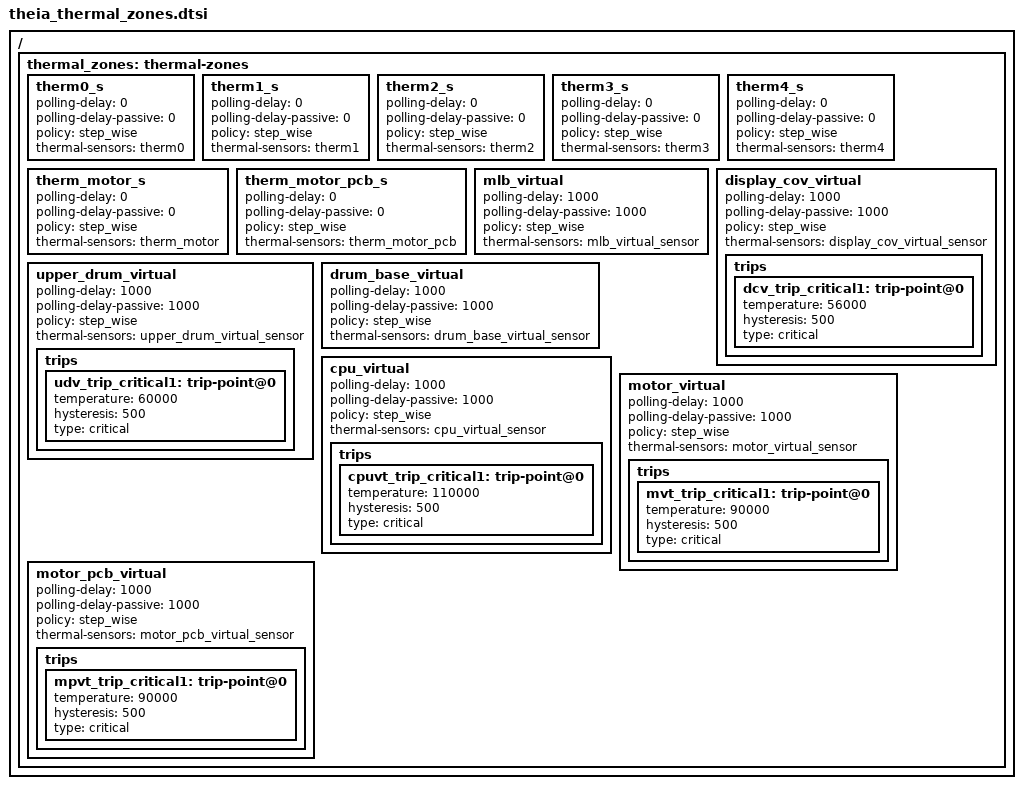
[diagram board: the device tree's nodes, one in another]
/*
 * arch/arm64/boot/dts/mediatek/theia_thermal_zones.dtsi
 *
 * Copyright (C) 2020 Amazon, Inc. All rights reserved.
 *
 * This program is free software; you can redistribute it and/or modify
 * it under the terms of the GNU General Public License as published by
 * the Free Software Foundation; either version 2 of the License, or
 * (at your option) any later version.
 *
 * This program is distributed in the hope that it will be useful, but WITHOUT
 * ANY WARRANTY; without even the implied warranty of MERCHANTABILITY or
 * FITNESS FOR A PARTICULAR PURPOSE.  See the GNU General Public License for
 * more details.
 *
*/

/ {

	thermal_zones: thermal-zones {

		therm0_s {
			polling-delay = <0>;
			polling-delay-passive = <0>;
			policy = "step_wise";
			thermal-sensors = <&therm0>;
		};

		therm1_s {
			polling-delay = <0>;
			polling-delay-passive = <0>;
			policy = "step_wise";
			thermal-sensors = <&therm1>;
		};

		therm2_s {
			polling-delay = <0>;
			polling-delay-passive = <0>;
			policy = "step_wise";
			thermal-sensors = <&therm2>;
		};

		therm3_s {
			polling-delay = <0>;
			polling-delay-passive = <0>;
			policy = "step_wise";
			thermal-sensors = <&therm3>;
		};

		therm4_s {
			polling-delay = <0>;
			polling-delay-passive = <0>;
			policy = "step_wise";
			thermal-sensors = <&therm4>;
		};

		therm_motor_s {
			polling-delay = <0>;
			polling-delay-passive = <0>;
			policy = "step_wise";
			thermal-sensors = <&therm_motor>;
		};

		therm_motor_pcb_s {
			polling-delay = <0>;
			polling-delay-passive = <0>;
			policy = "step_wise";
			thermal-sensors = <&therm_motor_pcb>;
		};

		mlb_virtual {
			polling-delay = <1000>;
			polling-delay-passive = <1000>;
			policy = "step_wise";
			thermal-sensors = <&mlb_virtual_sensor>;

		};

		display_cov_virtual {
			polling-delay = <1000>;
			polling-delay-passive = <1000>;
			policy = "step_wise";
			thermal-sensors = <&display_cov_virtual_sensor>;

			trips {
				dcv_trip_critical1: trip-point@0 {
					temperature = <56000>;
					hysteresis = <500>;
					type = "critical";
				};
			};
		};

		upper_drum_virtual {
			polling-delay = <1000>;
			polling-delay-passive = <1000>;
			policy = "step_wise";
			thermal-sensors = <&upper_drum_virtual_sensor>;

			trips {
				udv_trip_critical1: trip-point@0 {
					temperature = <60000>;
					hysteresis = <500>;
					type = "critical";
				};
			};
		};

		drum_base_virtual {
			polling-delay = <1000>;
			polling-delay-passive = <1000>;
			policy = "step_wise";
			thermal-sensors = <&drum_base_virtual_sensor>;
		};

		cpu_virtual: cpu_virtual {
			polling-delay = <1000>;
			polling-delay-passive = <1000>;
			policy = "step_wise";
			thermal-sensors = <&cpu_virtual_sensor>;

			trips {
				cpuvt_trip_critical1: trip-point@0 {
					temperature = <110000>;
					hysteresis = <500>;
					type = "critical";
				};
			};
		};

		motor_virtual: motor_virtual {
			polling-delay = <1000>;
			polling-delay-passive = <1000>;
			policy = "step_wise";
			thermal-sensors = <&motor_virtual_sensor>;

			trips {
				mvt_trip_critical1: trip-point@0 {
					temperature = <90000>;
					hysteresis = <500>;
					type = "critical";
				};
			};
		};

		motor_pcb_virtual: motor_pcb_virtual {
			polling-delay = <1000>;
			polling-delay-passive = <1000>;
			policy = "step_wise";
			thermal-sensors = <&motor_pcb_virtual_sensor>;

			trips {
				mpvt_trip_critical1: trip-point@0 {
					temperature = <90000>;
					hysteresis = <500>;
					type = "critical";
				};
			};
		};
	};
};
